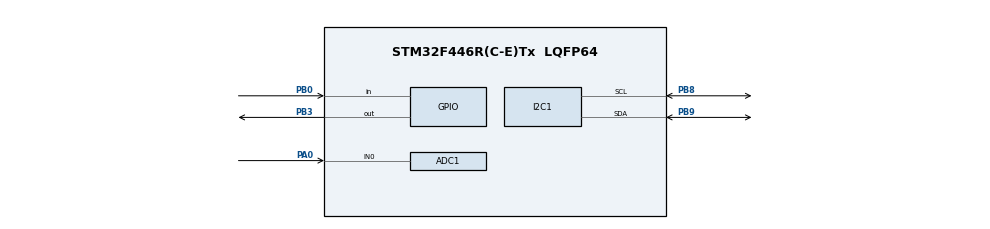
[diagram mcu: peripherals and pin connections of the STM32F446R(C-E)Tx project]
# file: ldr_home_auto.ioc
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ADC1.Channel-0\#ChannelRegularConversion=ADC_CHANNEL_0
ADC1.NbrOfConversionFlag=1
ADC1.Rank-0\#ChannelRegularConversion=1
ADC1.SamplingTime-0\#ChannelRegularConversion=ADC_SAMPLETIME_3CYCLES
ADC1.master=1
I2C1.I2C_Mode=I2C_Fast
Mcu.Family=STM32F4
Mcu.Name=STM32F446R(C-E)Tx
Mcu.Package=LQFP64
NVIC.PriorityGroup=NVIC_PRIORITYGROUP_4
PA0-WKUP.Signal=ADCx_IN0
PB0.GPIO_PuPd=GPIO_PULLUP
PB0.Signal=GPIO_Input
PB3.Signal=GPIO_Output
PB8.Mode=I2C
PB8.Signal=I2C1_SCL
PB9.Mode=I2C
PB9.Signal=I2C1_SDA
ProjectManager.HeapSize=0x200
ProjectManager.StackSize=0x400
ProjectManager.TargetToolchain=STM32CubeIDE
RCC.CortexFreq_Value=16000000
RCC.USBFreq_Value=96000000
RCC.VCOOutputFreq_Value=192000000
SH.ADCx_IN0.0=ADC1_IN0,IN0
board=custom

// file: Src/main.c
/* USER CODE BEGIN Header */
/**
  ******************************************************************************
  * @file           : main.c
  * @brief          : Main program body
  ******************************************************************************
  */
/* USER CODE END Header */

#include "main.h"

/* USER CODE BEGIN Includes */
#include "fonts.h"
#include "ssd1306.h"
#include <stdio.h>
/* USER CODE END Includes */

ADC_HandleTypeDef hadc1;
I2C_HandleTypeDef hi2c1;

/* USER CODE BEGIN PV */
uint32_t ldr_value;
char buffer[30];
#define THRESHOLD 2000
/* USER CODE END PV */

void SystemClock_Config(void);
static void MX_GPIO_Init(void);
static void MX_I2C1_Init(void);
static void MX_ADC1_Init(void);

int main(void)
{
  HAL_Init();
  SystemClock_Config();

  MX_GPIO_Init();
  MX_I2C1_Init();
  MX_ADC1_Init();

  /* OLED INIT */
  SSD1306_Init();

  /* START SCREEN */
  SSD1306_GotoXY(10,20);
  SSD1306_Puts("STEM SMART LAB", &Font_7x10, 1);
  SSD1306_UpdateScreen();
  HAL_Delay(2000);
  SSD1306_Fill(SSD1306_COLOR_BLACK);

  /* Infinite loop */
  while (1)
  {
    /* READ LDR */
    HAL_ADC_Start(&hadc1);
    HAL_ADC_PollForConversion(&hadc1, HAL_MAX_DELAY);
    ldr_value = HAL_ADC_GetValue(&hadc1);

    /* READ SWITCH */
    GPIO_PinState switch_state = HAL_GPIO_ReadPin(GPIOB, GPIO_PIN_0);

    /* SMOOTH CLEAR */
    SSD1306_Fill(SSD1306_COLOR_BLACK);

    /* DISPLAY LDR VALUE */
    sprintf(buffer, "LDR: %lu   ", ldr_value);
    SSD1306_GotoXY(0,0);
    SSD1306_Puts(buffer, &Font_7x10, 1);

    /* BAR GRAPH */
    int bar = (ldr_value * 100) / 4095;
    SSD1306_DrawRectangle(0, 15, 100, 10, 1);
    SSD1306_DrawFilledRectangle(0, 15, bar, 10, 1);

    /* LOGIC */
    if (switch_state == GPIO_PIN_RESET)
    {
      SSD1306_GotoXY(0,35);
      SSD1306_Puts("MODE: MANUAL OFF   ", &Font_7x10, 1);

      HAL_GPIO_WritePin(GPIOB, GPIO_PIN_3, GPIO_PIN_RESET);
    }
    else
    {
      if (ldr_value < THRESHOLD)
      {
        SSD1306_GotoXY(0,35);
        SSD1306_Puts("MODE: NIGHT   ", &Font_7x10, 1);

        SSD1306_GotoXY(0,50);
        SSD1306_Puts("LIGHT: ON   ", &Font_7x10, 1);

        HAL_GPIO_WritePin(GPIOB, GPIO_PIN_3, GPIO_PIN_SET);
      }
      else
      {
        SSD1306_GotoXY(0,35);
        SSD1306_Puts("MODE: DAY   ", &Font_7x10, 1);

        SSD1306_GotoXY(0,50);
        SSD1306_Puts("LIGHT: OFF   ", &Font_7x10, 1);

        HAL_GPIO_WritePin(GPIOB, GPIO_PIN_3, GPIO_PIN_RESET);
      }
    }

    SSD1306_UpdateScreen();

    HAL_Delay(300);   // smoother display (no flicker)
  }
}

static void MX_ADC1_Init(void)
{
  ADC_ChannelConfTypeDef sConfig = {0};

  hadc1.Instance = ADC1;
  hadc1.Init.ClockPrescaler = ADC_CLOCK_SYNC_PCLK_DIV2;
  hadc1.Init.Resolution = ADC_RESOLUTION_12B;
  hadc1.Init.ScanConvMode = DISABLE;
  hadc1.Init.ContinuousConvMode = DISABLE;
  hadc1.Init.DiscontinuousConvMode = DISABLE;
  hadc1.Init.ExternalTrigConvEdge = ADC_EXTERNALTRIGCONVEDGE_NONE;
  hadc1.Init.ExternalTrigConv = ADC_SOFTWARE_START;
  hadc1.Init.DataAlign = ADC_DATAALIGN_RIGHT;
  hadc1.Init.NbrOfConversion = 1;
  hadc1.Init.DMAContinuousRequests = DISABLE;
  hadc1.Init.EOCSelection = ADC_EOC_SINGLE_CONV;

  if (HAL_ADC_Init(&hadc1) != HAL_OK)
    Error_Handler();

  sConfig.Channel = ADC_CHANNEL_0;
  sConfig.Rank = 1;
  sConfig.SamplingTime = ADC_SAMPLETIME_3CYCLES;

  if (HAL_ADC_ConfigChannel(&hadc1, &sConfig) != HAL_OK)
    Error_Handler();
}

static void MX_I2C1_Init(void)
{
  hi2c1.Instance = I2C1;
  hi2c1.Init.ClockSpeed = 400000;
  hi2c1.Init.DutyCycle = I2C_DUTYCYCLE_2;
  hi2c1.Init.AddressingMode = I2C_ADDRESSINGMODE_7BIT;
  hi2c1.Init.OwnAddress1 = 0;
  hi2c1.Init.DualAddressMode = I2C_DUALADDRESS_DISABLE;
  hi2c1.Init.OwnAddress2 = 0;
  hi2c1.Init.GeneralCallMode = I2C_GENERALCALL_DISABLE;
  hi2c1.Init.NoStretchMode = I2C_NOSTRETCH_DISABLE;

  if (HAL_I2C_Init(&hi2c1) != HAL_OK)
    Error_Handler();
}

static void MX_GPIO_Init(void)
{
  GPIO_InitTypeDef GPIO_InitStruct = {0};

  __HAL_RCC_GPIOA_CLK_ENABLE();
  __HAL_RCC_GPIOB_CLK_ENABLE();

  HAL_GPIO_WritePin(GPIOB, GPIO_PIN_3, GPIO_PIN_RESET);

  /* PB0 → SWITCH */
  GPIO_InitStruct.Pin = GPIO_PIN_0;
  GPIO_InitStruct.Mode = GPIO_MODE_INPUT;
  GPIO_InitStruct.Pull = GPIO_PULLUP;
  HAL_GPIO_Init(GPIOB, &GPIO_InitStruct);

  /* PB3 → LED */
  GPIO_InitStruct.Pin = GPIO_PIN_3;
  GPIO_InitStruct.Mode = GPIO_MODE_OUTPUT_PP;
  GPIO_InitStruct.Pull = GPIO_NOPULL;
  GPIO_InitStruct.Speed = GPIO_SPEED_FREQ_LOW;
  HAL_GPIO_Init(GPIOB, &GPIO_InitStruct);
}

void SystemClock_Config(void)
{
  RCC_OscInitTypeDef RCC_OscInitStruct = {0};
  RCC_ClkInitTypeDef RCC_ClkInitStruct = {0};

  __HAL_RCC_PWR_CLK_ENABLE();
  __HAL_PWR_VOLTAGESCALING_CONFIG(PWR_REGULATOR_VOLTAGE_SCALE3);

  RCC_OscInitStruct.OscillatorType = RCC_OSCILLATORTYPE_HSI;
  RCC_OscInitStruct.HSIState = RCC_HSI_ON;
  RCC_OscInitStruct.PLL.PLLState = RCC_PLL_NONE;
  HAL_RCC_OscConfig(&RCC_OscInitStruct);

  RCC_ClkInitStruct.ClockType = RCC_CLOCKTYPE_HCLK | RCC_CLOCKTYPE_SYSCLK
                              | RCC_CLOCKTYPE_PCLK1 | RCC_CLOCKTYPE_PCLK2;
  RCC_ClkInitStruct.SYSCLKSource = RCC_SYSCLKSOURCE_HSI;
  HAL_RCC_ClockConfig(&RCC_ClkInitStruct, FLASH_LATENCY_0);
}

/**
  * @brief Error Handler
  */
void Error_Handler(void)
{
  __disable_irq();
  while (1) {}
}
